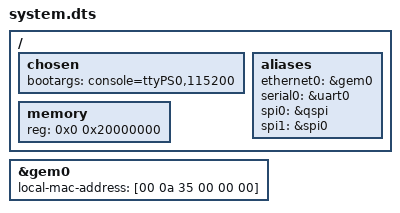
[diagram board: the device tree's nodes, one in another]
/*
 * CAUTION: This file is automatically generated by Xilinx.
 * Version: HSI 2016.2
 * Today is: Wed Sep 20 09:57:13 2017
*/


/dts-v1/;
/include/ "pcw.dtsi"
/include/ "zynq-7000.dtsi"
/include/ "pl.dtsi"
/ {
	chosen {
		bootargs = "console=ttyPS0,115200";
	};
	aliases {
		ethernet0 = &gem0;
		serial0 = &uart0;
		spi0 = &qspi;
		spi1 = &spi0;
	};
	memory {
		device_type = "memory";
		reg = <0x0 0x20000000>;
	};
};
&gem0 {
	local-mac-address = [00 0a 35 00 00 00];
};
